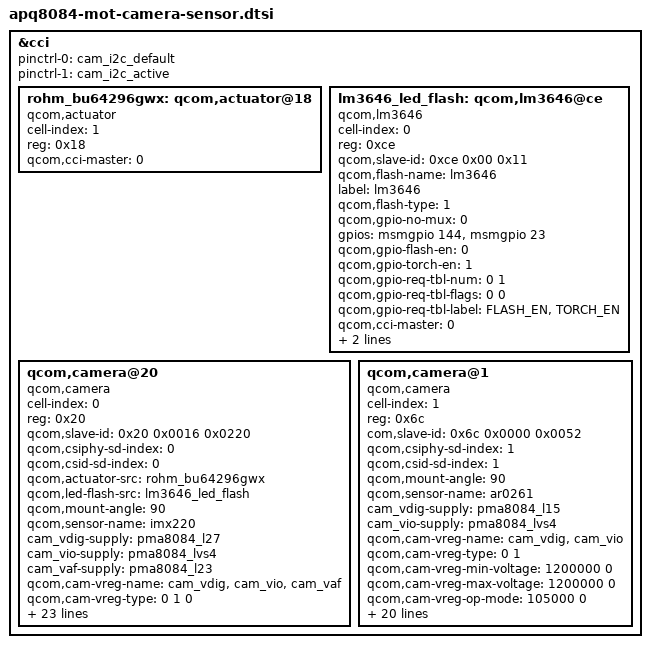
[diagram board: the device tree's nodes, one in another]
/*
 * Copyright (c) 2013, The Linux Foundation. All rights reserved.
 *
 * This program is free software; you can redistribute it and/or modify
 * it under the terms of the GNU General Public License version 2 and
 * only version 2 as published by the Free Software Foundation.
 *
 * This program is distributed in the hope that it will be useful,
 * but WITHOUT ANY WARRANTY; without even the implied warranty of
 * MERCHANTABILITY or FITNESS FOR A PARTICULAR PURPOSE.  See the
 * GNU General Public License for more details.
 */

&cci {
	pinctrl-names = "default", "active";
	pinctrl-0 = <&cam_i2c_default>;
	pinctrl-1 = <&cam_i2c_active>;

	rohm_bu64296gwx: qcom,actuator@18 {
		cell-index = <1>;
		reg = <0x18>;
		compatible = "qcom,actuator";
		qcom,cci-master = <0>;
	};

	lm3646_led_flash: qcom,lm3646@ce {
		cell-index = <0>;
		reg = <0xce>;
		qcom,slave-id = <0xce 0x00 0x11>;
		compatible = "qcom,lm3646";
		qcom,flash-name = "lm3646";
		label = "lm3646";
		qcom,flash-type = <1>;
		qcom,gpio-no-mux = <0>;
		gpios = <&msmgpio 144 0>,
			<&msmgpio 23 0>;
		qcom,gpio-flash-en = <0>;
		qcom,gpio-torch-en = <1>;
		qcom,gpio-req-tbl-num = <0 1>;
		qcom,gpio-req-tbl-flags = <0 0>;
		qcom,gpio-req-tbl-label = "FLASH_EN",
				"TORCH_EN";
		qcom,cci-master = <0>;
		pinctrl-names = "default", "active";
		pinctrl-0 = <&cam_flash_default>;
		pinctrl-1 = <&cam_flash_active>;
	};

	qcom,camera@20 {
		cell-index = <0>;
		compatible = "qcom,camera";
		reg = <0x20>;
		qcom,slave-id = <0x20 0x0016 0x0220>;
		qcom,csiphy-sd-index = <0>;
		qcom,csid-sd-index = <0>;
		qcom,actuator-src = <&rohm_bu64296gwx>;
		qcom,led-flash-src = <&lm3646_led_flash>;
		qcom,mount-angle = <90>;
		qcom,sensor-name = "imx220";
		cam_vdig-supply = <&pma8084_l27>;
		cam_vio-supply = <&pma8084_lvs4>;
		cam_vaf-supply = <&pma8084_l23>;
		qcom,cam-vreg-name = "cam_vdig", "cam_vio", "cam_vaf";
		qcom,cam-vreg-type = <0 1 0>;
		qcom,cam-vreg-min-voltage = <1050000 0 2700000>;
		qcom,cam-vreg-max-voltage = <1050000 0 2700000>;
		qcom,cam-vreg-op-mode = <105000 0 100000>;
		qcom,gpio-no-mux = <0>;
		gpios = <&msmgpio 15 0>,
			<&msmgpio 36 0>,
			<&msmgpio 120 0>;
		qcom,gpio-reset = <1>;
		qcom,gpio-vana = <2>;
		qcom,gpio-req-tbl-num = <0 1 2>;
		qcom,gpio-req-tbl-flags = <1 0 0>;
		qcom,gpio-req-tbl-label = "CAMIF_MCLK",
				"CAM_RESET1",
				"CAM_VANA";
		qcom,gpio-set-tbl-num = <1 1 1>;
		qcom,gpio-set-tbl-flags = <0 1 2>;
		qcom,gpio-set-tbl-delay = <1000 30000 1000>;
		qcom,csi-lane-assign = <0x4320>;
		qcom,csi-lane-mask = <0x1F>;
		qcom,sensor-position = <0>;
		qcom,sensor-mode = <0>;
		qcom,sensor-type = <0>;
		qcom,cci-master = <0>;
		status = "ok";
		pinctrl-names = "default", "active";
		pinctrl-0 = <&cam_mclk0_default &cam1_ctrl_default>;
		pinctrl-1 = <&cam_mclk0_active &cam1_ctrl_active>;
	};

	qcom,camera@1 {
		cell-index = <1>;
		compatible = "qcom,camera";
		reg = <0x6c>;
		com,slave-id = <0x6c 0x0000 0x0052>;
		qcom,csiphy-sd-index = <1>;
		qcom,csid-sd-index = <1>;
		qcom,mount-angle = <90>;
		qcom,sensor-name = "ar0261";
		cam_vdig-supply = <&pma8084_l15>;
		cam_vio-supply = <&pma8084_lvs4>;
		qcom,cam-vreg-name = "cam_vdig", "cam_vio";
		qcom,cam-vreg-type = <0 1>;
		qcom,cam-vreg-min-voltage = <1200000 0>;
		qcom,cam-vreg-max-voltage = <1200000 0>;
		qcom,cam-vreg-op-mode = <105000 0>;
		qcom,gpio-no-mux = <0>;
		gpios = <&msmgpio 17 0>,
			<&msmgpio 38 0>,
			<&msmgpio 37 0>;
		qcom,gpio-reset = <1>;
		qcom,gpio-vana = <2>;
		qcom,gpio-req-tbl-num = <0 1 2>;
		qcom,gpio-req-tbl-flags = <1 0 0>;
		qcom,gpio-req-tbl-label = "CAMIF_MCLK",
					"CAM_RESET",
					"CAM_AVDD";
		qcom,gpio-set-tbl-num = <1 1>;
		qcom,gpio-set-tbl-flags = <0 2>;
		qcom,gpio-set-tbl-delay = <1000 4000>;
		qcom,csi-lane-assign = <0x4320>;
		qcom,csi-lane-mask = <0x07>;
		qcom,sensor-position = <1>;
		qcom,sensor-mode = <1>;
		qcom,sensor-type = <0>;
		qcom,cci-master = <0>;
		status = "ok";
		pinctrl-names = "default", "active";
		pinctrl-0 = <&cam_mclk2_default &cam2_ctrl_default>;
		pinctrl-1 = <&cam_mclk2_active &cam2_ctrl_active>;
	};

};
